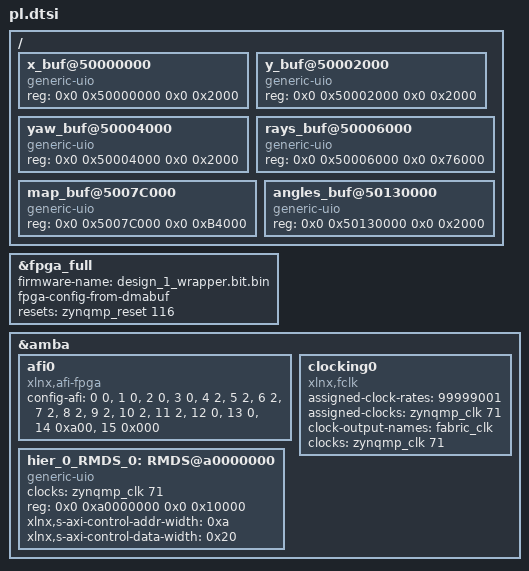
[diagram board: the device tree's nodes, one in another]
/*
 * CAUTION: This file is automatically generated by Xilinx.
 * Version: XSCT 2022.1
 * Today is: Thu Jun 23 18:35:30 2022
 */


/dts-v1/;
/plugin/;
/ {
	fragment@0 {
		target = <&fpga_full>;
		overlay0: __overlay__ {
			#address-cells = <2>;
			#size-cells = <2>;
			firmware-name = "design_1_wrapper.bit.bin";
			fpga-config-from-dmabuf;
                        resets = <&zynqmp_reset 116>;
		};
	};
	fragment@1 {
		target = <&amba>;
		overlay1: __overlay__ {
			afi0: afi0 {
				compatible = "xlnx,afi-fpga";
				config-afi = < 0 0>, <1 0>, <2 0>, <3 0>, <4 2>, <5 2>, <6 2>, <7 2>, <8 2>, <9 2>, <10 2>, <11 2>, <12 0>, <13 0>, <14 0xa00>, <15 0x000>;
			};
			clocking0: clocking0 {
				#clock-cells = <0>;
				assigned-clock-rates = <99999001>;
				assigned-clocks = <&zynqmp_clk 71>;
				clock-output-names = "fabric_clk";
				clocks = <&zynqmp_clk 71>;
				compatible = "xlnx,fclk";
			};
		};
	};
	fragment@2 {
		target = <&amba>;
		overlay2: __overlay__ {
			#address-cells = <2>;
			#size-cells = <2>;
			hier_0_RMDS_0: RMDS@a0000000 {
				/* This is a place holder node for a custom IP, user may need to update the entries */
				clock-names = "ap_clk";
				clocks = <&zynqmp_clk 71>;
				compatible = "generic-uio";
				reg = <0x0 0xa0000000 0x0 0x10000>;
				xlnx,s-axi-control-addr-width = <0xa>;
				xlnx,s-axi-control-data-width = <0x20>;
			};
		};
	};
       fragment@3 {
                target-path = "/";
                overlay3:__overlay__ {
                        #address-cells = <2>;
                        #size-cells = <2>;
                        x_buf@50000000{
                                        compatible = "generic-uio";
                                        reg = <0x0 0x50000000 0x0 0x2000>;
                        };
                        y_buf@50002000{
                                        compatible = "generic-uio";
                                        reg = <0x0 0x50002000 0x0 0x2000>;
                        };

                         yaw_buf@50004000{
                                        compatible = "generic-uio";
                                        reg = <0x0 0x50004000 0x0 0x2000>;
                        };

                        rays_buf@50006000{
                                        compatible = "generic-uio";
                                        reg = <0x0 0x50006000 0x0 0x76000>;
                        };

                        map_buf@5007C000{
                                        compatible = "generic-uio";
                                        reg = <0x0 0x5007C000 0x0 0xB4000>;
                        };
                        angles_buf@50130000{
                                        compatible = "generic-uio";
                                        reg = <0x0 0x50130000 0x0 0x2000>;
                        };


                };
        };

};
